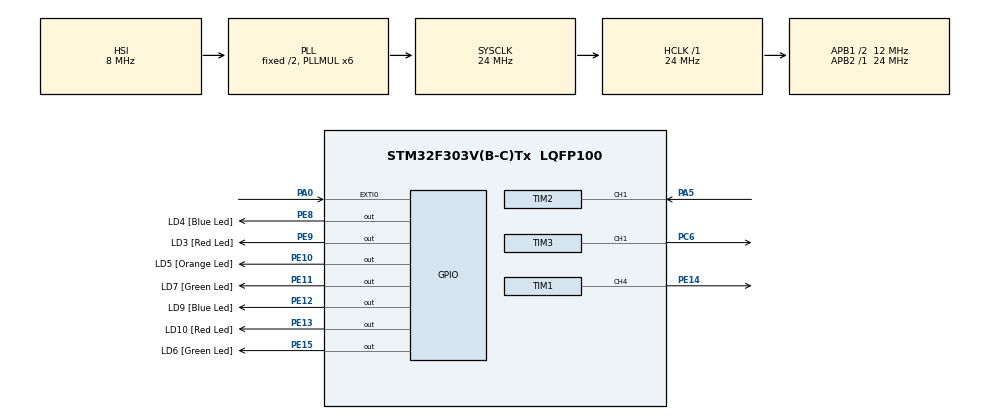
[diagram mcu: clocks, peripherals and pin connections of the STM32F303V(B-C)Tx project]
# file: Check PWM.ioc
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Dma.Request0=TIM3_CH1/TRIG
Dma.Request1=TIM2_CH1
Dma.Request2=TIM2_CH2/CH4
Dma.Request3=TIM1_CH4/TRIG/COM
Dma.TIM1_CH4/TRIG/COM.3.Direction=DMA_MEMORY_TO_PERIPH
Dma.TIM1_CH4/TRIG/COM.3.Instance=DMA1_Channel4
Dma.TIM1_CH4/TRIG/COM.3.MemDataAlignment=DMA_MDATAALIGN_HALFWORD
Dma.TIM1_CH4/TRIG/COM.3.MemInc=DMA_MINC_ENABLE
Dma.TIM1_CH4/TRIG/COM.3.Mode=DMA_CIRCULAR
Dma.TIM1_CH4/TRIG/COM.3.PeriphDataAlignment=DMA_PDATAALIGN_HALFWORD
Dma.TIM1_CH4/TRIG/COM.3.PeriphInc=DMA_PINC_DISABLE
Dma.TIM1_CH4/TRIG/COM.3.Priority=DMA_PRIORITY_LOW
Dma.TIM2_CH1.1.Direction=DMA_PERIPH_TO_MEMORY
Dma.TIM2_CH1.1.Instance=DMA1_Channel5
Dma.TIM2_CH1.1.MemDataAlignment=DMA_MDATAALIGN_WORD
Dma.TIM2_CH1.1.MemInc=DMA_MINC_ENABLE
Dma.TIM2_CH1.1.Mode=DMA_CIRCULAR
Dma.TIM2_CH1.1.PeriphDataAlignment=DMA_PDATAALIGN_WORD
Dma.TIM2_CH1.1.PeriphInc=DMA_PINC_DISABLE
Dma.TIM2_CH1.1.Priority=DMA_PRIORITY_LOW
Dma.TIM2_CH2/CH4.2.Direction=DMA_PERIPH_TO_MEMORY
Dma.TIM2_CH2/CH4.2.Instance=DMA1_Channel7
Dma.TIM2_CH2/CH4.2.MemDataAlignment=DMA_MDATAALIGN_WORD
Dma.TIM2_CH2/CH4.2.MemInc=DMA_MINC_ENABLE
Dma.TIM2_CH2/CH4.2.Mode=DMA_CIRCULAR
Dma.TIM2_CH2/CH4.2.PeriphDataAlignment=DMA_PDATAALIGN_WORD
Dma.TIM2_CH2/CH4.2.PeriphInc=DMA_PINC_DISABLE
Dma.TIM2_CH2/CH4.2.Priority=DMA_PRIORITY_LOW
Dma.TIM3_CH1/TRIG.0.Direction=DMA_MEMORY_TO_PERIPH
Dma.TIM3_CH1/TRIG.0.Instance=DMA1_Channel6
Dma.TIM3_CH1/TRIG.0.MemDataAlignment=DMA_MDATAALIGN_HALFWORD
Dma.TIM3_CH1/TRIG.0.MemInc=DMA_MINC_ENABLE
Dma.TIM3_CH1/TRIG.0.Mode=DMA_CIRCULAR
Dma.TIM3_CH1/TRIG.0.PeriphDataAlignment=DMA_PDATAALIGN_HALFWORD
Dma.TIM3_CH1/TRIG.0.PeriphInc=DMA_PINC_DISABLE
Dma.TIM3_CH1/TRIG.0.Priority=DMA_PRIORITY_LOW
Mcu.Family=STM32F3
Mcu.Name=STM32F303V(B-C)Tx
Mcu.Package=LQFP100
NVIC.DMA1_Channel4_IRQn=true\:0\:0\:false\:false\:true\:false\:true
NVIC.DMA1_Channel5_IRQn=true\:0\:0\:false\:false\:true\:false\:true
NVIC.DMA1_Channel6_IRQn=true\:0\:0\:false\:false\:true\:false\:true
NVIC.DMA1_Channel7_IRQn=true\:0\:0\:false\:false\:true\:false\:true
NVIC.EXTI0_IRQn=true\:0\:0\:false\:false\:true\:true\:true
NVIC.PriorityGroup=NVIC_PRIORITYGROUP_0
PA0.GPIO_PuPd=GPIO_PULLDOWN
PA0.Signal=GPXTI0
PA13.GPIO_Label=SWDIO
PA13.Mode=Serial_Wire
PA13.Signal=SYS_JTMS-SWDIO
PA14.GPIO_Label=SWCLK
PA14.Mode=Serial_Wire
PA14.Signal=SYS_JTCK-SWCLK
PA5.Signal=S_TIM2_CH1_ETR
PB3.GPIO_Label=SWO
PB3.Signal=SYS_JTDO-TRACESWO
PC6.Signal=S_TIM3_CH1
PE10.GPIO_Label=LD5 [Orange Led]
PE10.Signal=GPIO_Output
PE11.GPIO_Label=LD7 [Green Led]
PE11.Signal=GPIO_Output
PE12.GPIO_Label=LD9 [Blue Led]
PE12.Signal=GPIO_Output
PE13.GPIO_Label=LD10 [Red Led]
PE13.Signal=GPIO_Output
PE14.Signal=S_TIM1_CH4
PE15.GPIO_Label=LD6 [Green Led]
PE15.Signal=GPIO_Output
PE8.GPIO_Label=LD4 [Blue Led]
PE8.Signal=GPIO_Output
PE9.GPIO_Label=LD3 [Red Led]
PE9.Signal=GPIO_Output
ProjectManager.HeapSize=0x200
ProjectManager.StackSize=0x400
ProjectManager.TargetToolchain=MDK-ARM V5
RCC.AHBFreq_Value=24000000
RCC.APB1CLKDivider=RCC_HCLK_DIV2
RCC.APB1Freq_Value=12000000
RCC.APB1TimFreq_Value=24000000
RCC.APB2Freq_Value=24000000
RCC.APB2TimFreq_Value=24000000
RCC.CortexFreq_Value=24000000
RCC.HCLKFreq_Value=24000000
RCC.HSE_VALUE=8000000
RCC.HSI_VALUE=8000000
RCC.LSE_VALUE=32768
RCC.PLLMUL=RCC_PLL_MUL6
RCC.SYSCLKFreq_VALUE=24000000
RCC.SYSCLKSourceVirtual=RCC_SYSCLKSOURCE_PLLCLK
RCC.USBFreq_Value=24000000
SH.S_TIM1_CH4.0=TIM1_CH4,PWM Generation4 CH4
SH.S_TIM2_CH1_ETR.0=TIM2_CH1,Input_Capture1_from_TI1
SH.S_TIM2_CH1_ETR.1=TIM2_CH1,TriggerSource_TI1FP1
SH.S_TIM3_CH1.0=TIM3_CH1,PWM Generation1 CH1
TIM1.Channel-PWM\ Generation4\ CH4=TIM_CHANNEL_4
TIM1.Period=20000
TIM1.Prescaler=23
TIM2.Channel-Input_Capture1_from_TI1=TIM_CHANNEL_1
TIM2.Channel-Input_Capture2_from_TI1_63=TIM_CHANNEL_2
TIM2.ICFilter_CH1=10
TIM2.ICPolarity_CH2=TIM_INPUTCHANNELPOLARITY_FALLING
TIM2.Period=500000
TIM2.Prescaler=23
TIM2.TIM_MasterSlaveMode=TIM_MASTERSLAVEMODE_DISABLE
TIM3.Channel-PWM\ Generation1\ CH1=TIM_CHANNEL_1
TIM3.Period=20000
TIM3.Prescaler=23
TIM3.Pulse-PWM\ Generation1\ CH1=1000
VP_TIM2_VS_ControllerModeReset.Mode=Reset Mode
VP_TIM2_VS_indirect_ch1.Mode=Input_Capture2_from_TI1_63
board=STM32F3DISCOVERY

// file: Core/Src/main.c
/* USER CODE BEGIN Header */
/**
  ******************************************************************************
  * @file           : main.c
  * @brief          : Main program body
  ******************************************************************************
  * @attention
  *
  * <h2><center>&copy; Copyright (c) 2021 STMicroelectronics.
  * All rights reserved.</center></h2>
  *
  * This software component is licensed by ST under BSD 3-Clause license,
  * the "License"; You may not use this file except in compliance with the
  * License. You may obtain a copy of the License at:
  *                        opensource.org/licenses/BSD-3-Clause
  *
  ******************************************************************************
  */
/* USER CODE END Header */
#include "main.h"

/* USER CODE BEGIN Includes */
#include "IMD.h"

/* USER CODE END Includes */

TIM_HandleTypeDef htim1;
TIM_HandleTypeDef htim2;
TIM_HandleTypeDef htim3;
DMA_HandleTypeDef hdma_tim1_ch4_trig_com;
DMA_HandleTypeDef hdma_tim2_ch1;
DMA_HandleTypeDef hdma_tim2_ch2_ch4;
DMA_HandleTypeDef hdma_tim3_ch1_trig;

/* USER CODE BEGIN PV */
//static uint16_t period[20] ;
//static uint16_t pulseWidth[20];
//static uint16_t GeneratedPulseWidth[400] = {0,};
	//uint32_t periodCall;
	//uint32_t pulseWidthCall;
//uint32_t Hval;
//uint32_t val;
extern uint32_t BuffPeriodIMD[20];
extern uint32_t BuffDutyCycleIMD[20];
//uint16_t bufftoCheck[20];
/* USER CODE END PV */

void SystemClock_Config(void);
static void MX_GPIO_Init(void);
static void MX_DMA_Init(void);
static void MX_TIM2_Init(void);
static void MX_TIM1_Init(void);
static void MX_TIM3_Init(void);

int main(void)
{

  /* MCU Configuration--------------------------------------------------------*/

  /* Reset of all peripherals, Initializes the Flash interface and the Systick. */
  HAL_Init();

  /* Configure the system clock */
  SystemClock_Config();

  /* Initialize all configured peripherals */
  MX_GPIO_Init();
  MX_DMA_Init();
  MX_TIM2_Init();
  MX_TIM1_Init();
  MX_TIM3_Init();
  /* USER CODE BEGIN 2 */
	//HAL_TIM_IC_Start_IT(&htim2, TIM_CHANNEL_1);
  //HAL_TIM_IC_Start_IT(&htim2, TIM_CHANNEL_2);
	//HAL_TIM_IC_Start_IT(&htim1, TIM_CHANNEL_1);
	//htim1.State = HAL_TIM_STATE_READY;
  //HAL_TIM_IC_Start_IT(&htim1, TIM_CHANNEL_2);
	HAL_TIM_IC_Start_DMA(&htim2, TIM_CHANNEL_1, BuffPeriodIMD, 20);
	HAL_TIM_IC_Start_DMA(&htim2, TIM_CHANNEL_2, BuffDutyCycleIMD, 20);

  //HAL_TIM_IC_Start_DMA(&htim1, TIM_CHANNEL_1, (uint32_t*)buffPulse, 1);
	//HAL_TIM_IC_Start_DMA(&htim1, TIM_CHANNEL_2, (uint32_t*)buffWidth, 1);

	//htim1.State = HAL_TIM_STATE_READY;
	//*Генерация Ш�?М - Начало*//

//  uint16_t ccr = 10000;
 // uint16_t i = 0;

  //for(; i < 200; i++)
  //{
  //        ccr = ccr ;
  //        GeneratedPulseWidth[i] = ccr;
  //}

  //for(; i < 400; i++)
  //{
  //        ccr = ccr ;
  //        GeneratedPulseWidth[i] = ccr;
  //}

  //HAL_TIM_PWM_Start_DMA(&htim3, TIM_CHANNEL_1, (uint32_t*)GeneratedPulseWidth, 400);
	//HAL_TIM_PWM_Start_DMA(&htim1, TIM_CHANNEL_4, (uint32_t*)GeneratedPulseWidth, 400);

		//*Генерация Ш�?М - Конец*//
	void HAL_GPIO_EXTI_Callback(uint16_t GPIO_Pin);
  /* USER CODE END 2 */

  /* Infinite loop */
  while (1)
  {

  }
}

void SystemClock_Config(void)
{
  RCC_OscInitTypeDef RCC_OscInitStruct = {0};
  RCC_ClkInitTypeDef RCC_ClkInitStruct = {0};
  RCC_PeriphCLKInitTypeDef PeriphClkInit = {0};

  /** Initializes the RCC Oscillators according to the specified parameters
  * in the RCC_OscInitTypeDef structure.
  */
  RCC_OscInitStruct.OscillatorType = RCC_OSCILLATORTYPE_HSI;
  RCC_OscInitStruct.HSIState = RCC_HSI_ON;
  RCC_OscInitStruct.HSICalibrationValue = RCC_HSICALIBRATION_DEFAULT;
  RCC_OscInitStruct.PLL.PLLState = RCC_PLL_ON;
  RCC_OscInitStruct.PLL.PLLSource = RCC_PLLSOURCE_HSI;
  RCC_OscInitStruct.PLL.PLLMUL = RCC_PLL_MUL6;
  if (HAL_RCC_OscConfig(&RCC_OscInitStruct) != HAL_OK)
  {
    Error_Handler();
  }
  /** Initializes the CPU, AHB and APB buses clocks
  */
  RCC_ClkInitStruct.ClockType = RCC_CLOCKTYPE_HCLK|RCC_CLOCKTYPE_SYSCLK
                              |RCC_CLOCKTYPE_PCLK1|RCC_CLOCKTYPE_PCLK2;
  RCC_ClkInitStruct.SYSCLKSource = RCC_SYSCLKSOURCE_PLLCLK;
  RCC_ClkInitStruct.AHBCLKDivider = RCC_SYSCLK_DIV1;
  RCC_ClkInitStruct.APB1CLKDivider = RCC_HCLK_DIV2;
  RCC_ClkInitStruct.APB2CLKDivider = RCC_HCLK_DIV1;

  if (HAL_RCC_ClockConfig(&RCC_ClkInitStruct, FLASH_LATENCY_0) != HAL_OK)
  {
    Error_Handler();
  }
  PeriphClkInit.PeriphClockSelection = RCC_PERIPHCLK_TIM1;
  PeriphClkInit.Tim1ClockSelection = RCC_TIM1CLK_HCLK;
  if (HAL_RCCEx_PeriphCLKConfig(&PeriphClkInit) != HAL_OK)
  {
    Error_Handler();
  }
}

static void MX_TIM1_Init(void)
{

  TIM_MasterConfigTypeDef sMasterConfig = {0};
  TIM_OC_InitTypeDef sConfigOC = {0};
  TIM_BreakDeadTimeConfigTypeDef sBreakDeadTimeConfig = {0};

  htim1.Instance = TIM1;
  htim1.Init.Prescaler = 23;
  htim1.Init.CounterMode = TIM_COUNTERMODE_UP;
  htim1.Init.Period = 20000;
  htim1.Init.ClockDivision = TIM_CLOCKDIVISION_DIV1;
  htim1.Init.RepetitionCounter = 0;
  htim1.Init.AutoReloadPreload = TIM_AUTORELOAD_PRELOAD_DISABLE;
  if (HAL_TIM_PWM_Init(&htim1) != HAL_OK)
  {
    Error_Handler();
  }
  sMasterConfig.MasterOutputTrigger = TIM_TRGO_RESET;
  sMasterConfig.MasterOutputTrigger2 = TIM_TRGO2_RESET;
  sMasterConfig.MasterSlaveMode = TIM_MASTERSLAVEMODE_DISABLE;
  if (HAL_TIMEx_MasterConfigSynchronization(&htim1, &sMasterConfig) != HAL_OK)
  {
    Error_Handler();
  }
  sConfigOC.OCMode = TIM_OCMODE_PWM1;
  sConfigOC.Pulse = 0;
  sConfigOC.OCPolarity = TIM_OCPOLARITY_HIGH;
  sConfigOC.OCFastMode = TIM_OCFAST_DISABLE;
  sConfigOC.OCIdleState = TIM_OCIDLESTATE_RESET;
  sConfigOC.OCNIdleState = TIM_OCNIDLESTATE_RESET;
  if (HAL_TIM_PWM_ConfigChannel(&htim1, &sConfigOC, TIM_CHANNEL_4) != HAL_OK)
  {
    Error_Handler();
  }
  sBreakDeadTimeConfig.OffStateRunMode = TIM_OSSR_DISABLE;
  sBreakDeadTimeConfig.OffStateIDLEMode = TIM_OSSI_DISABLE;
  sBreakDeadTimeConfig.LockLevel = TIM_LOCKLEVEL_OFF;
  sBreakDeadTimeConfig.DeadTime = 0;
  sBreakDeadTimeConfig.BreakState = TIM_BREAK_DISABLE;
  sBreakDeadTimeConfig.BreakPolarity = TIM_BREAKPOLARITY_HIGH;
  sBreakDeadTimeConfig.BreakFilter = 0;
  sBreakDeadTimeConfig.Break2State = TIM_BREAK2_DISABLE;
  sBreakDeadTimeConfig.Break2Polarity = TIM_BREAK2POLARITY_HIGH;
  sBreakDeadTimeConfig.Break2Filter = 0;
  sBreakDeadTimeConfig.AutomaticOutput = TIM_AUTOMATICOUTPUT_DISABLE;
  if (HAL_TIMEx_ConfigBreakDeadTime(&htim1, &sBreakDeadTimeConfig) != HAL_OK)
  {
    Error_Handler();
  }
  HAL_TIM_MspPostInit(&htim1);

}

static void MX_TIM2_Init(void)
{

  TIM_SlaveConfigTypeDef sSlaveConfig = {0};
  TIM_MasterConfigTypeDef sMasterConfig = {0};
  TIM_IC_InitTypeDef sConfigIC = {0};

  htim2.Instance = TIM2;
  htim2.Init.Prescaler = 23;
  htim2.Init.CounterMode = TIM_COUNTERMODE_UP;
  htim2.Init.Period = 500000;
  htim2.Init.ClockDivision = TIM_CLOCKDIVISION_DIV1;
  htim2.Init.AutoReloadPreload = TIM_AUTORELOAD_PRELOAD_DISABLE;
  if (HAL_TIM_Base_Init(&htim2) != HAL_OK)
  {
    Error_Handler();
  }
  if (HAL_TIM_IC_Init(&htim2) != HAL_OK)
  {
    Error_Handler();
  }
  sSlaveConfig.SlaveMode = TIM_SLAVEMODE_RESET;
  sSlaveConfig.InputTrigger = TIM_TS_TI1FP1;
  sSlaveConfig.TriggerPolarity = TIM_INPUTCHANNELPOLARITY_RISING;
  sSlaveConfig.TriggerFilter = 0;
  if (HAL_TIM_SlaveConfigSynchro(&htim2, &sSlaveConfig) != HAL_OK)
  {
    Error_Handler();
  }
  sMasterConfig.MasterOutputTrigger = TIM_TRGO_RESET;
  sMasterConfig.MasterSlaveMode = TIM_MASTERSLAVEMODE_DISABLE;
  if (HAL_TIMEx_MasterConfigSynchronization(&htim2, &sMasterConfig) != HAL_OK)
  {
    Error_Handler();
  }
  sConfigIC.ICPolarity = TIM_INPUTCHANNELPOLARITY_RISING;
  sConfigIC.ICSelection = TIM_ICSELECTION_DIRECTTI;
  sConfigIC.ICPrescaler = TIM_ICPSC_DIV1;
  sConfigIC.ICFilter = 10;
  if (HAL_TIM_IC_ConfigChannel(&htim2, &sConfigIC, TIM_CHANNEL_1) != HAL_OK)
  {
    Error_Handler();
  }
  sConfigIC.ICPolarity = TIM_INPUTCHANNELPOLARITY_FALLING;
  sConfigIC.ICSelection = TIM_ICSELECTION_INDIRECTTI;
  sConfigIC.ICFilter = 0;
  if (HAL_TIM_IC_ConfigChannel(&htim2, &sConfigIC, TIM_CHANNEL_2) != HAL_OK)
  {
    Error_Handler();
  }

}

static void MX_TIM3_Init(void)
{

  TIM_MasterConfigTypeDef sMasterConfig = {0};
  TIM_OC_InitTypeDef sConfigOC = {0};

  htim3.Instance = TIM3;
  htim3.Init.Prescaler = 23;
  htim3.Init.CounterMode = TIM_COUNTERMODE_UP;
  htim3.Init.Period = 20000;
  htim3.Init.ClockDivision = TIM_CLOCKDIVISION_DIV1;
  htim3.Init.AutoReloadPreload = TIM_AUTORELOAD_PRELOAD_DISABLE;
  if (HAL_TIM_PWM_Init(&htim3) != HAL_OK)
  {
    Error_Handler();
  }
  sMasterConfig.MasterOutputTrigger = TIM_TRGO_RESET;
  sMasterConfig.MasterSlaveMode = TIM_MASTERSLAVEMODE_DISABLE;
  if (HAL_TIMEx_MasterConfigSynchronization(&htim3, &sMasterConfig) != HAL_OK)
  {
    Error_Handler();
  }
  sConfigOC.OCMode = TIM_OCMODE_PWM1;
  sConfigOC.Pulse = 1000;
  sConfigOC.OCPolarity = TIM_OCPOLARITY_HIGH;
  sConfigOC.OCFastMode = TIM_OCFAST_DISABLE;
  if (HAL_TIM_PWM_ConfigChannel(&htim3, &sConfigOC, TIM_CHANNEL_1) != HAL_OK)
  {
    Error_Handler();
  }
  HAL_TIM_MspPostInit(&htim3);

}

static void MX_DMA_Init(void)
{

  /* DMA controller clock enable */
  __HAL_RCC_DMA1_CLK_ENABLE();

  /* DMA interrupt init */
  /* DMA1_Channel4_IRQn interrupt configuration */
  HAL_NVIC_SetPriority(DMA1_Channel4_IRQn, 0, 0);
  HAL_NVIC_EnableIRQ(DMA1_Channel4_IRQn);
  /* DMA1_Channel5_IRQn interrupt configuration */
  HAL_NVIC_SetPriority(DMA1_Channel5_IRQn, 0, 0);
  HAL_NVIC_EnableIRQ(DMA1_Channel5_IRQn);
  /* DMA1_Channel6_IRQn interrupt configuration */
  HAL_NVIC_SetPriority(DMA1_Channel6_IRQn, 0, 0);
  HAL_NVIC_EnableIRQ(DMA1_Channel6_IRQn);
  /* DMA1_Channel7_IRQn interrupt configuration */
  HAL_NVIC_SetPriority(DMA1_Channel7_IRQn, 0, 0);
  HAL_NVIC_EnableIRQ(DMA1_Channel7_IRQn);

}

static void MX_GPIO_Init(void)
{
  GPIO_InitTypeDef GPIO_InitStruct = {0};

  /* GPIO Ports Clock Enable */
  __HAL_RCC_GPIOA_CLK_ENABLE();
  __HAL_RCC_GPIOE_CLK_ENABLE();
  __HAL_RCC_GPIOC_CLK_ENABLE();
  __HAL_RCC_GPIOB_CLK_ENABLE();

  /*Configure GPIO pin Output Level */
  HAL_GPIO_WritePin(GPIOE, LD4_Pin|LD3_Pin|LD5_Pin|LD7_Pin
                          |LD9_Pin|LD10_Pin|LD6_Pin, GPIO_PIN_RESET);

  /*Configure GPIO pin : PA0 */
  GPIO_InitStruct.Pin = GPIO_PIN_0;
  GPIO_InitStruct.Mode = GPIO_MODE_IT_RISING;
  GPIO_InitStruct.Pull = GPIO_PULLDOWN;
  HAL_GPIO_Init(GPIOA, &GPIO_InitStruct);

  /*Configure GPIO pins : LD4_Pin LD3_Pin LD5_Pin LD7_Pin
                           LD9_Pin LD10_Pin LD6_Pin */
  GPIO_InitStruct.Pin = LD4_Pin|LD3_Pin|LD5_Pin|LD7_Pin
                          |LD9_Pin|LD10_Pin|LD6_Pin;
  GPIO_InitStruct.Mode = GPIO_MODE_OUTPUT_PP;
  GPIO_InitStruct.Pull = GPIO_NOPULL;
  GPIO_InitStruct.Speed = GPIO_SPEED_FREQ_LOW;
  HAL_GPIO_Init(GPIOE, &GPIO_InitStruct);

  /* EXTI interrupt init*/
  HAL_NVIC_SetPriority(EXTI0_IRQn, 0, 0);
  HAL_NVIC_EnableIRQ(EXTI0_IRQn);

}

/* USER CODE BEGIN 4 */
//uint32_t GETPCLK2TIM(void) //  Получение значения тактирования на таймере 1
//{
//  /* Get PCLK2 frequency */
//  uint32_t pclk2 = HAL_RCC_GetPCLK2Freq();
//
//  /* Get PCLK2 prescaler */
//  if((RCC->CFGR & RCC_CFGR_PPRE1) == 0)
//  {
//    /* PCLK2 prescaler equal to 1 => TIMCLK = PCLK2 */
//    return (pclk2);
//  }
//  else
//  {
//    /* PCLK2 prescaler different from 1 => TIMCLK = 2 * PCLK2 */
//    return(2 * pclk2);
//  }
//
//}

/*void HAL_TIM_IC_CaptureCallback(TIM_HandleTypeDef *htim)
{

	uint32_t frequency=0;
	float DutyCycleIMD=0.0f;
	float InsulationResistance=0.0f;// сопротивление изоляции в МОм
	if (htim->Instance == TIM_FOR_IMD_PWM)
	{
		if(htim->Channel == TIM_CHANNEL_FOR_IMD_PWM)
		{
		TIM2->CNT = 0;
		periodCall = HAL_TIM_ReadCapturedValue(&htim2, TIM_CHANNEL_1); //микросекунды
		pulseWidthCall = HAL_TIM_ReadCapturedValue(&htim2, TIM_CHANNEL_2);
		}
	}
//	frequency=1*( GETPCLK2TIM()%(htim2.Init.Prescaler+1))%periodCall;// - Гц, так период в мкс, чтобы его перевести в секунды его \
//																																нужно поделить на TIM1_CLOCK%(htim2.Init.Prescaler+1) :\
//																																(1/(period/TIM1_CLOCK%(htim2.Init.Prescaler+1))=\
//																																=1*TIM1_CLOCK%(htim2.Init.Prescaler+1)/period), чтобы получить частоту в Гц
//	DutyCycleIMD=pulseWidthCall/periodCall;
//	if (DutyCycleIMD<=0.05)
//	{
//		InsulationResistance=50; // МОм и больше
//	}
//	else if (DutyCycleIMD>0.05)
//	{
//		InsulationResistance=((90*1200)/(DutyCycleIMD*100-5)-1200)/1000; //МОм
//	}
}
void HAL_TIM_PWM_PulseFinishedHalfCpltCallback(TIM_HandleTypeDef *htim)
{
         Hval = HAL_TIM_ReadCapturedValue(&htim2, TIM_CHANNEL_1);

}

void HAL_TIM_PWM_PulseFinishedCallback(TIM_HandleTypeDef *htim)
{
         val = HAL_TIM_ReadCapturedValue(&htim2, TIM_CHANNEL_1);

}*/

/* USER CODE END 4 */

void Error_Handler(void)
{
  __disable_irq();
  while (1)
  {
  }
}

/************************ (C) COPYRIGHT STMicroelectronics *****END OF FILE****/
